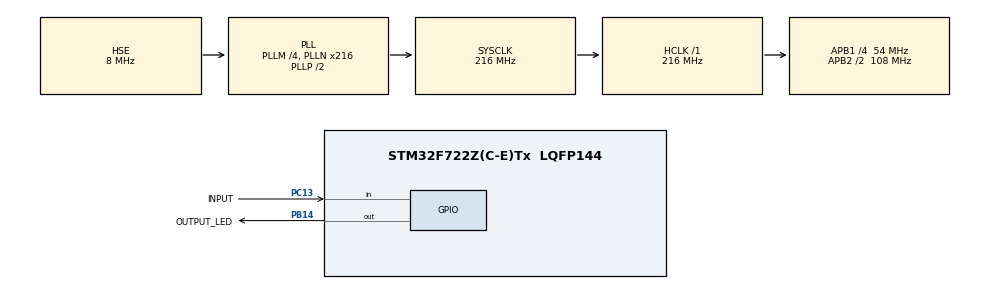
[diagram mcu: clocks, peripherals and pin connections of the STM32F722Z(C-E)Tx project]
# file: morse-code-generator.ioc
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CORTEX_M7.default_mode_Activation=1
Mcu.Family=STM32F7
Mcu.Name=STM32F722Z(C-E)Tx
Mcu.Package=LQFP144
NVIC.PriorityGroup=NVIC_PRIORITYGROUP_4
PB14.GPIO_Label=OUTPUT_LED
PB14.Signal=GPIO_Output
PC13.GPIO_Label=INPUT
PC13.GPIO_PuPd=GPIO_PULLDOWN
PC13.Signal=GPIO_Input
PH0-OSC_IN.Mode=HSE-External-Clock-Source
PH0-OSC_IN.Signal=RCC_OSC_IN
PH1-OSC_OUT.Mode=HSE-External-Clock-Source
PH1-OSC_OUT.Signal=RCC_OSC_OUT
ProjectManager.HeapSize=0x200
ProjectManager.StackSize=0x400
ProjectManager.TargetToolchain=Makefile
RCC.48MHZClocksFreq_Value=24000000
RCC.AHBFreq_Value=216000000
RCC.APB1CLKDivider=RCC_HCLK_DIV4
RCC.APB1Freq_Value=54000000
RCC.APB1TimFreq_Value=108000000
RCC.APB2CLKDivider=RCC_HCLK_DIV2
RCC.APB2Freq_Value=108000000
RCC.APB2TimFreq_Value=216000000
RCC.CortexFreq_Value=216000000
RCC.HCLKFreq_Value=216000000
RCC.HSE_VALUE=8000000
RCC.HSI_VALUE=16000000
RCC.LSE_VALUE=32768
RCC.PLLM=4
RCC.PLLMUL=RCC_PLL_MUL9
RCC.PLLN=216
RCC.PLLQ=9
RCC.PLLSourceVirtual=RCC_PLLSOURCE_HSE
RCC.PRESCALERUSB=RCC_USBCLKSOURCE_PLL_DIV1_5
RCC.SYSCLKFreq_VALUE=216000000
RCC.SYSCLKSource=RCC_SYSCLKSOURCE_PLLCLK
RCC.SYSCLKSourceVirtual=RCC_SYSCLKSOURCE_PLLCLK
RCC.USBFreq_Value=48000000
RCC.VCOOutputFreq_Value=432000000
board=NUCLEO-F722ZE

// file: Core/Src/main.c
/* USER CODE BEGIN Header */
/**
  ******************************************************************************
  * @file           : main.c
  * @brief          : Main program body
  ******************************************************************************
  * @attention
  *
  * Copyright (c) 2026 STMicroelectronics.
  * All rights reserved.
  *
  * This software is licensed under terms that can be found in the LICENSE file
  * in the root directory of this software component.
  * If no LICENSE file comes with this software, it is provided AS-IS.
  *
  ******************************************************************************
  */
/* USER CODE END Header */
#include "main.h"

/* USER CODE BEGIN Includes */

#include <stdio.h>
#include <string.h>
#include <ctype.h>

#define MAX_OUTPUT_LEN 512
#define MORSE_UNIT 500

static const char message[] = "HELLO";
char output[MAX_OUTPUT_LEN] = {0};

/* USER CODE END Includes */

void SystemClock_Config(void);
static void MPU_Config(void);
static void MX_GPIO_Init(void);

//Decoder Functions
static const char * char_converter(char c);
static void morse_decoder(const char * message, char * output);

//Blink Functions
static void morse_dot(void);
static void morse_slash(void);
static void morse_mod(void);

int main(void)
{

  /* USER CODE BEGIN 1 */

  morse_decoder(message, output);

  /* USER CODE END 1 */

  /* MPU Configuration--------------------------------------------------------*/
  MPU_Config();

  /* MCU Configuration--------------------------------------------------------*/

  /* Reset of all peripherals, Initializes the Flash interface and the Systick. */
  HAL_Init();

  /* Configure the system clock */
  SystemClock_Config();

  /* Initialize all configured peripherals */
  MX_GPIO_Init();

  /* Infinite loop */
  while (1)
  {

    for(int i = 0; output[i] != '\0'; i++) {

      switch(output[i]) {

        case '.' :
          morse_dot();
          HAL_Delay(MORSE_UNIT);
          break;
        case '-' :
          morse_slash();
          HAL_Delay(MORSE_UNIT);
          break;
        case '|' :
          morse_mod();
          HAL_Delay(MORSE_UNIT);
          break;

        default : break;

      }

    }

  }
}

void SystemClock_Config(void)
{
  RCC_OscInitTypeDef RCC_OscInitStruct = {0};
  RCC_ClkInitTypeDef RCC_ClkInitStruct = {0};

  /** Configure the main internal regulator output voltage
  */
  __HAL_RCC_PWR_CLK_ENABLE();
  __HAL_PWR_VOLTAGESCALING_CONFIG(PWR_REGULATOR_VOLTAGE_SCALE1);

  /** Initializes the RCC Oscillators according to the specified parameters
  * in the RCC_OscInitTypeDef structure.
  */
  RCC_OscInitStruct.OscillatorType = RCC_OSCILLATORTYPE_HSE;
  RCC_OscInitStruct.HSEState = RCC_HSE_BYPASS;
  RCC_OscInitStruct.PLL.PLLState = RCC_PLL_ON;
  RCC_OscInitStruct.PLL.PLLSource = RCC_PLLSOURCE_HSE;
  RCC_OscInitStruct.PLL.PLLM = 4;
  RCC_OscInitStruct.PLL.PLLN = 216;
  RCC_OscInitStruct.PLL.PLLP = RCC_PLLP_DIV2;
  RCC_OscInitStruct.PLL.PLLQ = 9;
  if (HAL_RCC_OscConfig(&RCC_OscInitStruct) != HAL_OK)
  {
    Error_Handler();
  }

  /** Activate the Over-Drive mode
  */
  if (HAL_PWREx_EnableOverDrive() != HAL_OK)
  {
    Error_Handler();
  }

  /** Initializes the CPU, AHB and APB buses clocks
  */
  RCC_ClkInitStruct.ClockType = RCC_CLOCKTYPE_HCLK|RCC_CLOCKTYPE_SYSCLK
                              |RCC_CLOCKTYPE_PCLK1|RCC_CLOCKTYPE_PCLK2;
  RCC_ClkInitStruct.SYSCLKSource = RCC_SYSCLKSOURCE_PLLCLK;
  RCC_ClkInitStruct.AHBCLKDivider = RCC_SYSCLK_DIV1;
  RCC_ClkInitStruct.APB1CLKDivider = RCC_HCLK_DIV4;
  RCC_ClkInitStruct.APB2CLKDivider = RCC_HCLK_DIV2;

  if (HAL_RCC_ClockConfig(&RCC_ClkInitStruct, FLASH_LATENCY_7) != HAL_OK)
  {
    Error_Handler();
  }
}

static void MX_GPIO_Init(void)
{
  GPIO_InitTypeDef GPIO_InitStruct = {0};

  /* GPIO Ports Clock Enable */
  __HAL_RCC_GPIOC_CLK_ENABLE();
  __HAL_RCC_GPIOH_CLK_ENABLE();
  __HAL_RCC_GPIOB_CLK_ENABLE();

  /*Configure GPIO pin Output Level */
  HAL_GPIO_WritePin(OUTPUT_LED_GPIO_Port, OUTPUT_LED_Pin, GPIO_PIN_RESET);

  /*Configure GPIO pin : INPUT_Pin */
  GPIO_InitStruct.Pin = INPUT_Pin;
  GPIO_InitStruct.Mode = GPIO_MODE_INPUT;
  GPIO_InitStruct.Pull = GPIO_PULLDOWN;
  HAL_GPIO_Init(INPUT_GPIO_Port, &GPIO_InitStruct);

  /*Configure GPIO pin : OUTPUT_LED_Pin */
  GPIO_InitStruct.Pin = OUTPUT_LED_Pin;
  GPIO_InitStruct.Mode = GPIO_MODE_OUTPUT_PP;
  GPIO_InitStruct.Pull = GPIO_NOPULL;
  GPIO_InitStruct.Speed = GPIO_SPEED_FREQ_LOW;
  HAL_GPIO_Init(OUTPUT_LED_GPIO_Port, &GPIO_InitStruct);

}

/* USER CODE BEGIN 4 */

// Morse Constructor Functions

static const char * char_converter(char c) {

    switch(c) {

    case 'A': return ".-";
    case 'B': return "-...";
    case 'C': return "-.-.";
    case 'D': return "-..";
    case 'E': return ".";
    case 'F': return "..-.";
    case 'G': return "--.";
    case 'H': return "....";
    case 'I': return "..";
    case 'J': return ".---";
    case 'K': return "-.-";
    case 'L': return ".-..";
    case 'M': return "--";
    case 'N': return "-.";
    case 'O': return "---";
    case 'P': return ".--.";
    case 'Q': return "--.-";
    case 'R': return ".-.";
    case 'S': return "...";
    case 'T': return "-";
    case 'U': return "..-";
    case 'V': return "...-";
    case 'W': return ".--";
    case 'X': return "-..-";
    case 'Y': return "-.--";
    case 'Z': return "--..";

    default: return "";

  }

}

static void morse_decoder(const char * message, char * output) {

  output[0] = '\0';

  int i = 0;

  for(i = 0; message[i] != '\0'; i++) {

    const char * morse = char_converter(message[i]);

    strcat(output, morse);
    strcat(output, "|");

  }

}

// LED Blink Functions

static void morse_dot(void) {

  HAL_GPIO_WritePin(GPIOB, OUTPUT_LED_Pin, GPIO_PIN_SET);
  HAL_Delay(500);
  HAL_GPIO_WritePin(GPIOB, OUTPUT_LED_Pin, GPIO_PIN_RESET);

}

static void morse_slash(void) {

  HAL_GPIO_WritePin(GPIOB, OUTPUT_LED_Pin, GPIO_PIN_SET);
  HAL_Delay(1500);
  HAL_GPIO_WritePin(GPIOB, OUTPUT_LED_Pin, GPIO_PIN_RESET);

}

static void morse_mod(void) {

  HAL_GPIO_WritePin(GPIOB, OUTPUT_LED_Pin, GPIO_PIN_RESET);
  HAL_Delay(1000);

}

/* USER CODE END 4 */

 /* MPU Configuration */

void MPU_Config(void)
{
  MPU_Region_InitTypeDef MPU_InitStruct = {0};

  /* Disables the MPU */
  HAL_MPU_Disable();

  /** Initializes and configures the Region and the memory to be protected
  */
  MPU_InitStruct.Enable = MPU_REGION_ENABLE;
  MPU_InitStruct.Number = MPU_REGION_NUMBER0;
  MPU_InitStruct.BaseAddress = 0x0;
  MPU_InitStruct.Size = MPU_REGION_SIZE_4GB;
  MPU_InitStruct.SubRegionDisable = 0x87;
  MPU_InitStruct.TypeExtField = MPU_TEX_LEVEL0;
  MPU_InitStruct.AccessPermission = MPU_REGION_NO_ACCESS;
  MPU_InitStruct.DisableExec = MPU_INSTRUCTION_ACCESS_DISABLE;
  MPU_InitStruct.IsShareable = MPU_ACCESS_SHAREABLE;
  MPU_InitStruct.IsCacheable = MPU_ACCESS_NOT_CACHEABLE;
  MPU_InitStruct.IsBufferable = MPU_ACCESS_NOT_BUFFERABLE;

  HAL_MPU_ConfigRegion(&MPU_InitStruct);
  /* Enables the MPU */
  HAL_MPU_Enable(MPU_PRIVILEGED_DEFAULT);

}

void Error_Handler(void)
{
  __disable_irq();
  while (1)
  {
  }
}
